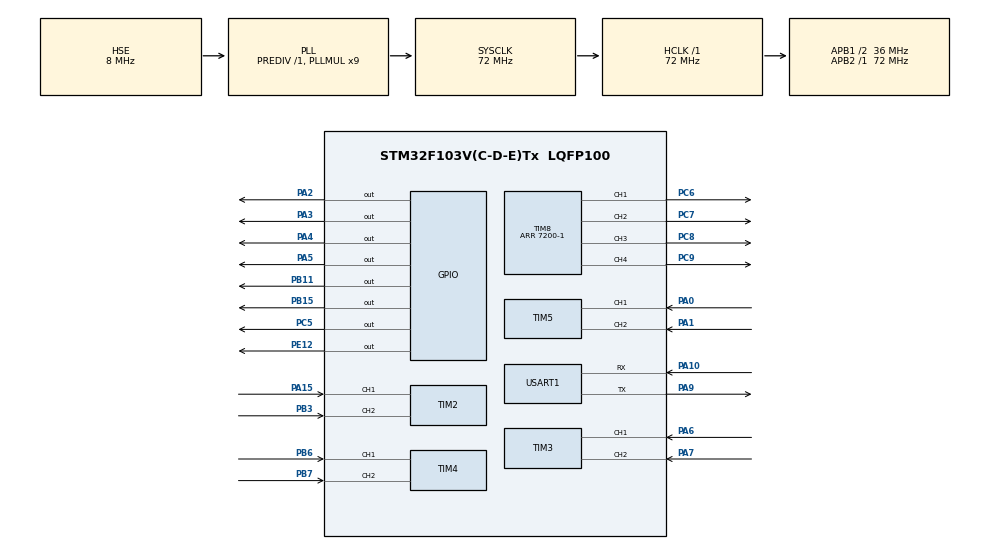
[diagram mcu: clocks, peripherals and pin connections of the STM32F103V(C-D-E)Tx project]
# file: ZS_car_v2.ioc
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Mcu.Family=STM32F1
Mcu.Name=STM32F103V(C-D-E)Tx
Mcu.Package=LQFP100
NVIC.PriorityGroup=NVIC_PRIORITYGROUP_4
OSC_IN.Mode=HSE-External-Oscillator
OSC_IN.Signal=RCC_OSC_IN
OSC_OUT.Mode=HSE-External-Oscillator
OSC_OUT.Signal=RCC_OSC_OUT
PA0-WKUP.Signal=S_TIM5_CH1
PA1.Signal=S_TIM5_CH2
PA10.Mode=Asynchronous
PA10.Signal=USART1_RX
PA13.Mode=Serial_Wire
PA13.Signal=SYS_JTMS-SWDIO
PA14.Mode=Serial_Wire
PA14.Signal=SYS_JTCK-SWCLK
PA15.Signal=S_TIM2_CH1_ETR
PA2.Signal=GPIO_Output
PA3.Signal=GPIO_Output
PA4.Signal=GPIO_Output
PA5.Signal=GPIO_Output
PA6.Signal=S_TIM3_CH1
PA7.Signal=S_TIM3_CH2
PA9.Mode=Asynchronous
PA9.Signal=USART1_TX
PB11.Signal=GPIO_Output
PB15.Signal=GPIO_Output
PB3.Signal=S_TIM2_CH2
PB6.Signal=S_TIM4_CH1
PB7.Signal=S_TIM4_CH2
PC14-OSC32_IN.Mode=LSE-External-Oscillator
PC14-OSC32_IN.Signal=RCC_OSC32_IN
PC15-OSC32_OUT.Mode=LSE-External-Oscillator
PC15-OSC32_OUT.Signal=RCC_OSC32_OUT
PC5.Signal=GPIO_Output
PC6.Signal=S_TIM8_CH1
PC7.Signal=S_TIM8_CH2
PC8.Signal=S_TIM8_CH3
PC9.Signal=S_TIM8_CH4
PE12.Signal=GPIO_Output
ProjectManager.HeapSize=0x200
ProjectManager.StackSize=0x400
ProjectManager.TargetToolchain=SW4STM32
RCC.AHBFreq_Value=72000000
RCC.APB1CLKDivider=RCC_HCLK_DIV2
RCC.APB1Freq_Value=36000000
RCC.APB1TimFreq_Value=72000000
RCC.APB2Freq_Value=72000000
RCC.APB2TimFreq_Value=72000000
RCC.HCLKFreq_Value=72000000
RCC.PLLMUL=RCC_PLL_MUL9
RCC.PLLSourceVirtual=RCC_PLLSOURCE_HSE
RCC.SYSCLKFreq_VALUE=72000000
RCC.SYSCLKSource=RCC_SYSCLKSOURCE_PLLCLK
RCC.USBFreq_Value=72000000
SH.S_TIM2_CH1_ETR.0=TIM2_CH1,Encoder_Interface
SH.S_TIM2_CH2.0=TIM2_CH2,Encoder_Interface
SH.S_TIM3_CH1.0=TIM3_CH1,Encoder_Interface
SH.S_TIM3_CH2.0=TIM3_CH2,Encoder_Interface
SH.S_TIM4_CH1.0=TIM4_CH1,Encoder_Interface
SH.S_TIM4_CH2.0=TIM4_CH2,Encoder_Interface
SH.S_TIM5_CH1.0=TIM5_CH1,Encoder_Interface
SH.S_TIM5_CH2.0=TIM5_CH2,Encoder_Interface
SH.S_TIM8_CH1.0=TIM8_CH1,PWM Generation1 CH1
SH.S_TIM8_CH2.0=TIM8_CH2,PWM Generation2 CH2
SH.S_TIM8_CH3.0=TIM8_CH3,PWM Generation3 CH3
SH.S_TIM8_CH4.0=TIM8_CH4,PWM Generation4 CH4
TIM2.EncoderMode=TIM_ENCODERMODE_TI12
TIM3.EncoderMode=TIM_ENCODERMODE_TI12
TIM4.EncoderMode=TIM_ENCODERMODE_TI12
TIM5.EncoderMode=TIM_ENCODERMODE_TI12
TIM8.Channel-PWM\ Generation1\ CH1=TIM_CHANNEL_1
TIM8.Channel-PWM\ Generation2\ CH2=TIM_CHANNEL_2
TIM8.Channel-PWM\ Generation3\ CH3=TIM_CHANNEL_3
TIM8.Channel-PWM\ Generation4\ CH4=TIM_CHANNEL_4
TIM8.Period=7200-1
USART1.VirtualMode=VM_ASYNC
board=custom

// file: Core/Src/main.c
/* USER CODE BEGIN Header */
/**
  ******************************************************************************
  * @file           : main.c
  * @brief          : Main program body
  ******************************************************************************
  * @attention
  *
  * <h2><center>&copy; Copyright (c) 2022 STMicroelectronics.
  * All rights reserved.</center></h2>
  *
  * This software component is licensed by ST under BSD 3-Clause license,
  * the "License"; You may not use this file except in compliance with the
  * License. You may obtain a copy of the License at:
  *                        opensource.org/licenses/BSD-3-Clause
  *
  ******************************************************************************
  */
/* USER CODE END Header */
#include "main.h"
#include "tim.h"
#include "usart.h"
#include "gpio.h"

/* USER CODE BEGIN Includes */

/*printf输出重定向*/
#include <stdio.h>
#ifdef __GNUC__
#define PUTCHAR_PROTOTYPE int __io_putchar(int ch)
#else
#define PUTCHAR_PROTOTYPE int fputc(int ch, FILE *f)
#endif
PUTCHAR_PROTOTYPE{
    // 参数1： 使用哪个usart ,参数2： 字符， 参数3：输出数量， 参数4：超时等待时间
    HAL_UART_Transmit(&huart1 , (uint8_t *)&ch, 1 , 0xffff);
    return ch;
}

/*导入头文件*/
#include "./zhangshuo_code/cppmain.h"
#include "./zhangshuo_code/my_log.h"
#include <stdio.h>
/* USER CODE END Includes */

void SystemClock_Config(void);

int main(void)
{

  /* MCU Configuration--------------------------------------------------------*/

  /* Reset of all peripherals, Initializes the Flash interface and the Systick. */
  HAL_Init();

  /* Configure the system clock */
  SystemClock_Config();

  /* Initialize all configured peripherals */
  MX_GPIO_Init();
  MX_USART1_UART_Init();
  MX_TIM8_Init();
  MX_TIM2_Init();
  MX_TIM3_Init();
  MX_TIM4_Init();
  MX_TIM5_Init();
  /* USER CODE BEGIN 2 */
  Init();
  /* USER CODE END 2 */

  /* Infinite loop */
  /* USER CODE BEGIN WHILE */
  while (1)
  {
      Tick();
    /* USER CODE END WHILE */

  }
}

void SystemClock_Config(void)
{
  RCC_OscInitTypeDef RCC_OscInitStruct = {0};
  RCC_ClkInitTypeDef RCC_ClkInitStruct = {0};

  /** Initializes the RCC Oscillators according to the specified parameters
  * in the RCC_OscInitTypeDef structure.
  */
  RCC_OscInitStruct.OscillatorType = RCC_OSCILLATORTYPE_HSE;
  RCC_OscInitStruct.HSEState = RCC_HSE_ON;
  RCC_OscInitStruct.HSEPredivValue = RCC_HSE_PREDIV_DIV1;
  RCC_OscInitStruct.HSIState = RCC_HSI_ON;
  RCC_OscInitStruct.PLL.PLLState = RCC_PLL_ON;
  RCC_OscInitStruct.PLL.PLLSource = RCC_PLLSOURCE_HSE;
  RCC_OscInitStruct.PLL.PLLMUL = RCC_PLL_MUL9;
  if (HAL_RCC_OscConfig(&RCC_OscInitStruct) != HAL_OK)
  {
    Error_Handler();
  }
  /** Initializes the CPU, AHB and APB buses clocks
  */
  RCC_ClkInitStruct.ClockType = RCC_CLOCKTYPE_HCLK|RCC_CLOCKTYPE_SYSCLK
                              |RCC_CLOCKTYPE_PCLK1|RCC_CLOCKTYPE_PCLK2;
  RCC_ClkInitStruct.SYSCLKSource = RCC_SYSCLKSOURCE_PLLCLK;
  RCC_ClkInitStruct.AHBCLKDivider = RCC_SYSCLK_DIV1;
  RCC_ClkInitStruct.APB1CLKDivider = RCC_HCLK_DIV2;
  RCC_ClkInitStruct.APB2CLKDivider = RCC_HCLK_DIV1;

  if (HAL_RCC_ClockConfig(&RCC_ClkInitStruct, FLASH_LATENCY_2) != HAL_OK)
  {
    Error_Handler();
  }
}

void Error_Handler(void)
{
  __disable_irq();
  while (1)
  {
  }
}

/************************ (C) COPYRIGHT STMicroelectronics *****END OF FILE****/
